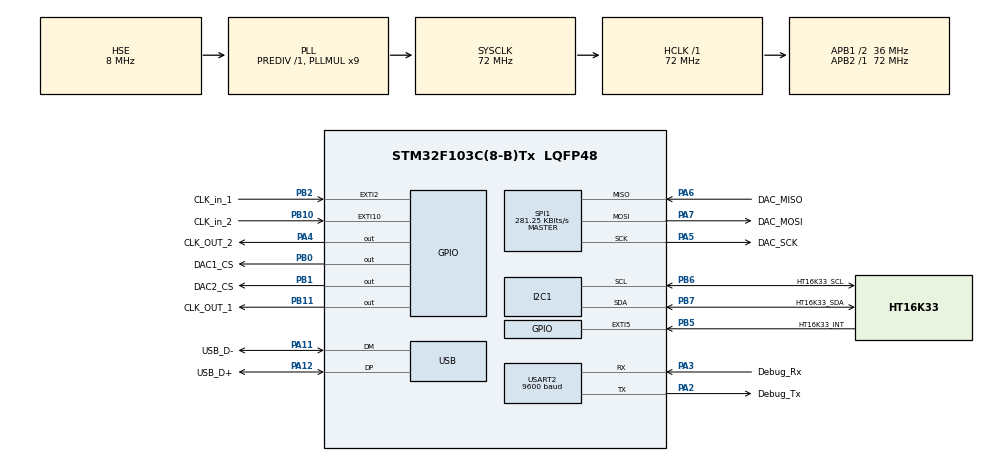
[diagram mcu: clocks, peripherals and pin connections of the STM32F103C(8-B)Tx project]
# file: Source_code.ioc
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FREERTOS.Tasks01=thread_LED,-1,64,process_LED,Default,NULL,Dynamic,NULL,NULL;thread_pulsador,-3,64,process_pulsador,Default,NULL,Dynamic,NULL,NULL
FREERTOS.configMINIMAL_STACK_SIZE=64
Mcu.Family=STM32F1
Mcu.Name=STM32F103C(8-B)Tx
Mcu.Package=LQFP48
NVIC.PriorityGroup=NVIC_PRIORITYGROUP_4
NVIC.TIM1_UP_IRQn=true\:0\:0\:false\:false\:true\:false\:false\:true
NVIC.TimeBase=TIM1_UP_IRQn
NVIC.TimeBaseIP=TIM1
PA11.GPIO_Label=USB_D-
PA11.Mode=Device
PA11.Signal=USB_DM
PA12.GPIO_Label=USB_D+
PA12.Mode=Device
PA12.Signal=USB_DP
PA13.GPIO_Label=JTAG_SWDIO
PA13.Mode=Serial_Wire
PA13.Signal=SYS_JTMS-SWDIO
PA14.GPIO_Label=JTAG_CLK
PA14.Mode=Serial_Wire
PA14.Signal=SYS_JTCK-SWCLK
PA2.GPIO_Label=Debug_Tx
PA2.Mode=Asynchronous
PA2.Signal=USART2_TX
PA3.GPIO_Label=Debug_Rx
PA3.Mode=Asynchronous
PA3.Signal=USART2_RX
PA4.GPIO_Label=CLK_OUT_2
PA4.Signal=GPIO_Output
PA5.GPIO_Label=DAC_SCK
PA5.Mode=Full_Duplex_Master
PA5.Signal=SPI1_SCK
PA6.GPIO_Label=DAC_MISO
PA6.Mode=Full_Duplex_Master
PA6.Signal=SPI1_MISO
PA7.GPIO_Label=DAC_MOSI
PA7.Mode=Full_Duplex_Master
PA7.Signal=SPI1_MOSI
PB0.GPIO_Label=DAC1_CS
PB0.Signal=GPIO_Output
PB1.GPIO_Label=DAC2_CS
PB1.Signal=GPIO_Output
PB10.GPIO_Label=CLK_in_2
PB10.Signal=GPXTI10
PB11.GPIO_Label=CLK_OUT_1
PB11.Signal=GPIO_Output
PB2.GPIO_Label=CLK_in_1
PB2.Signal=GPXTI2
PB5.GPIO_Label=HT16K33_INT
PB5.Signal=GPXTI5
PB6.GPIO_Label=HT16K33_SCL
PB6.Mode=I2C
PB6.Signal=I2C1_SCL
PB7.GPIO_Label=HT16K33_SDA
PB7.Mode=I2C
PB7.Signal=I2C1_SDA
PD0-OSC_IN.GPIO_Label=XTAL_IN
PD0-OSC_IN.Mode=HSE-External-Oscillator
PD0-OSC_IN.Signal=RCC_OSC_IN
PD1-OSC_OUT.GPIO_Label=XTAL_OUT
PD1-OSC_OUT.Mode=HSE-External-Oscillator
PD1-OSC_OUT.Signal=RCC_OSC_OUT
ProjectManager.HeapSize=0x200
ProjectManager.StackSize=0x400
ProjectManager.TargetToolchain=Makefile
RCC.AHBFreq_Value=72000000
RCC.APB1CLKDivider=RCC_HCLK_DIV2
RCC.APB1Freq_Value=36000000
RCC.APB1TimFreq_Value=72000000
RCC.APB2Freq_Value=72000000
RCC.APB2TimFreq_Value=72000000
RCC.HCLKFreq_Value=72000000
RCC.PLLMUL=RCC_PLL_MUL9
RCC.SYSCLKFreq_VALUE=72000000
RCC.SYSCLKSource=RCC_SYSCLKSOURCE_PLLCLK
RCC.USBFreq_Value=48000000
RCC.USBPrescaler=RCC_USBCLKSOURCE_PLL_DIV1_5
SPI1.BaudRatePrescaler=SPI_BAUDRATEPRESCALER_256
SPI1.CalculateBaudRate=281.25 KBits/s
SPI1.Direction=SPI_DIRECTION_2LINES
SPI1.Mode=SPI_MODE_MASTER
SPI1.VirtualType=VM_MASTER
USART2.BaudRate=9600
USART2.VirtualMode=VM_ASYNC
VP_FREERTOS_VS_CMSIS_V1.Mode=CMSIS_V1
VP_SYS_VS_tim1.Mode=TIM1
board=custom

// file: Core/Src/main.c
/* USER CODE BEGIN Header */
/**
  ******************************************************************************
  * @file           : main.c
  * @brief          : Main program body
  ******************************************************************************
  * @attention
  *
  * <h2><center>&copy; Copyright (c) 2020 STMicroelectronics.
  * All rights reserved.</center></h2>
  *
  * This software component is licensed by ST under Ultimate Liberty license
  * SLA0044, the "License"; You may not use this file except in compliance with
  * the License. You may obtain a copy of the License at:
  *                             www.st.com/SLA0044
  *
  ******************************************************************************
  */
/* USER CODE END Header */

#include "main.h"
#include "cmsis_os.h"
#include "i2c.h"
#include "spi.h"
#include "usart.h"
#include "usb.h"
#include "gpio.h"

/* USER CODE BEGIN Includes */
#include "drivers.h"

/* USER CODE END Includes */

void SystemClock_Config(void);
void MX_FREERTOS_Init(void);

int main(void)
{

  /* MCU Configuration--------------------------------------------------------*/

  /* Reset of all peripherals, Initializes the Flash interface and the Systick. */
  HAL_Init();

  /* Configure the system clock */
  SystemClock_Config();

  /* Initialize all configured peripherals */
  MX_GPIO_Init();
  MX_USB_PCD_Init();
  MX_SPI1_Init();
  MX_USART2_UART_Init();
  MX_I2C1_Init();

  /* Call init function for freertos objects (in freertos.c) */
  MX_FREERTOS_Init();

  /* Start scheduler */
  osKernelStart();

  /* We should never get here as control is now taken by the scheduler */

  /* Infinite loop */
  while (1)
  {

  }
}

void SystemClock_Config(void)
{
  RCC_OscInitTypeDef RCC_OscInitStruct = {0};
  RCC_ClkInitTypeDef RCC_ClkInitStruct = {0};
  RCC_PeriphCLKInitTypeDef PeriphClkInit = {0};

  /** Initializes the CPU, AHB and APB busses clocks
  */
  RCC_OscInitStruct.OscillatorType = RCC_OSCILLATORTYPE_HSE;
  RCC_OscInitStruct.HSEState = RCC_HSE_ON;
  RCC_OscInitStruct.HSEPredivValue = RCC_HSE_PREDIV_DIV1;
  RCC_OscInitStruct.HSIState = RCC_HSI_ON;
  RCC_OscInitStruct.PLL.PLLState = RCC_PLL_ON;
  RCC_OscInitStruct.PLL.PLLSource = RCC_PLLSOURCE_HSE;
  RCC_OscInitStruct.PLL.PLLMUL = RCC_PLL_MUL9;
  if (HAL_RCC_OscConfig(&RCC_OscInitStruct) != HAL_OK)
  {
    Error_Handler();
  }
  /** Initializes the CPU, AHB and APB busses clocks
  */
  RCC_ClkInitStruct.ClockType = RCC_CLOCKTYPE_HCLK|RCC_CLOCKTYPE_SYSCLK
                              |RCC_CLOCKTYPE_PCLK1|RCC_CLOCKTYPE_PCLK2;
  RCC_ClkInitStruct.SYSCLKSource = RCC_SYSCLKSOURCE_PLLCLK;
  RCC_ClkInitStruct.AHBCLKDivider = RCC_SYSCLK_DIV1;
  RCC_ClkInitStruct.APB1CLKDivider = RCC_HCLK_DIV2;
  RCC_ClkInitStruct.APB2CLKDivider = RCC_HCLK_DIV1;

  if (HAL_RCC_ClockConfig(&RCC_ClkInitStruct, FLASH_LATENCY_2) != HAL_OK)
  {
    Error_Handler();
  }
  PeriphClkInit.PeriphClockSelection = RCC_PERIPHCLK_USB;
  PeriphClkInit.UsbClockSelection = RCC_USBCLKSOURCE_PLL_DIV1_5;
  if (HAL_RCCEx_PeriphCLKConfig(&PeriphClkInit) != HAL_OK)
  {
    Error_Handler();
  }
}

void HAL_TIM_PeriodElapsedCallback(TIM_HandleTypeDef *htim)
{
  if (htim->Instance == TIM1) {
    HAL_IncTick();
  }
}

void Error_Handler(void)
{
}

/************************ (C) COPYRIGHT STMicroelectronics *****END OF FILE****/

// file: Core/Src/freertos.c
/* USER CODE BEGIN Header */
/**
  ******************************************************************************
  * File Name          : freertos.c
  * Description        : Code for freertos applications
  ******************************************************************************
  * @attention
  *
  * <h2><center>&copy; Copyright (c) 2020 STMicroelectronics.
  * All rights reserved.</center></h2>
  *
  * This software component is licensed by ST under Ultimate Liberty license
  * SLA0044, the "License"; You may not use this file except in compliance with
  * the License. You may obtain a copy of the License at:
  *                             www.st.com/SLA0044
  *
  ******************************************************************************
  */
/* USER CODE END Header */

#include "FreeRTOS.h"
#include "task.h"
#include "main.h"
#include "cmsis_os.h"

/* USER CODE BEGIN Includes */
#include "drivers.h"
/* USER CODE END Includes */

osThreadId thread_LEDHandle;
osThreadId thread_pulsadorHandle;

void process_LED(void const * argument);
void process_pulsador(void const * argument);

void MX_FREERTOS_Init(void); /* (MISRA C 2004 rule 8.1) */

void MX_FREERTOS_Init(void) {

  /* Create the thread(s) */
  /* definition and creation of thread_LED */
  osThreadDef(thread_LED, process_LED, osPriorityBelowNormal, 0, 64);
  thread_LEDHandle = osThreadCreate(osThread(thread_LED), NULL);

  /* definition and creation of thread_pulsador */
  osThreadDef(thread_pulsador, process_pulsador, osPriorityIdle, 0, 64);
  thread_pulsadorHandle = osThreadCreate(osThread(thread_pulsador), NULL);

}

void process_LED(void const * argument)
{

  /* USER CODE BEGIN process_LED */

	/* Infinite loop */
	for(;;)
	{
		for(int i = 0; i < MAX_LED; i++)
		{
			//write_led(i, 1);
			write_led(i, estat_led[i]);
		}

		osDelay(1);
	}
  /* USER CODE END process_LED */
}

void process_pulsador(void const * argument)
{
  /* USER CODE BEGIN process_pulsador */

	for(int i = 0; i < MAX_LED; i++)
	{
		estat_led[i] = 1;
	}

  /* Infinite loop */
  for(;;)
  {
	  //osDelay(10000);
		/*
		for(int i = 0; i < MAX_LED; i++)
		{
			estat_led[i] = 0;
			osDelay(500);
		}
		*/
  }
  /* USER CODE END process_pulsador */
}

/************************ (C) COPYRIGHT STMicroelectronics *****END OF FILE****/
